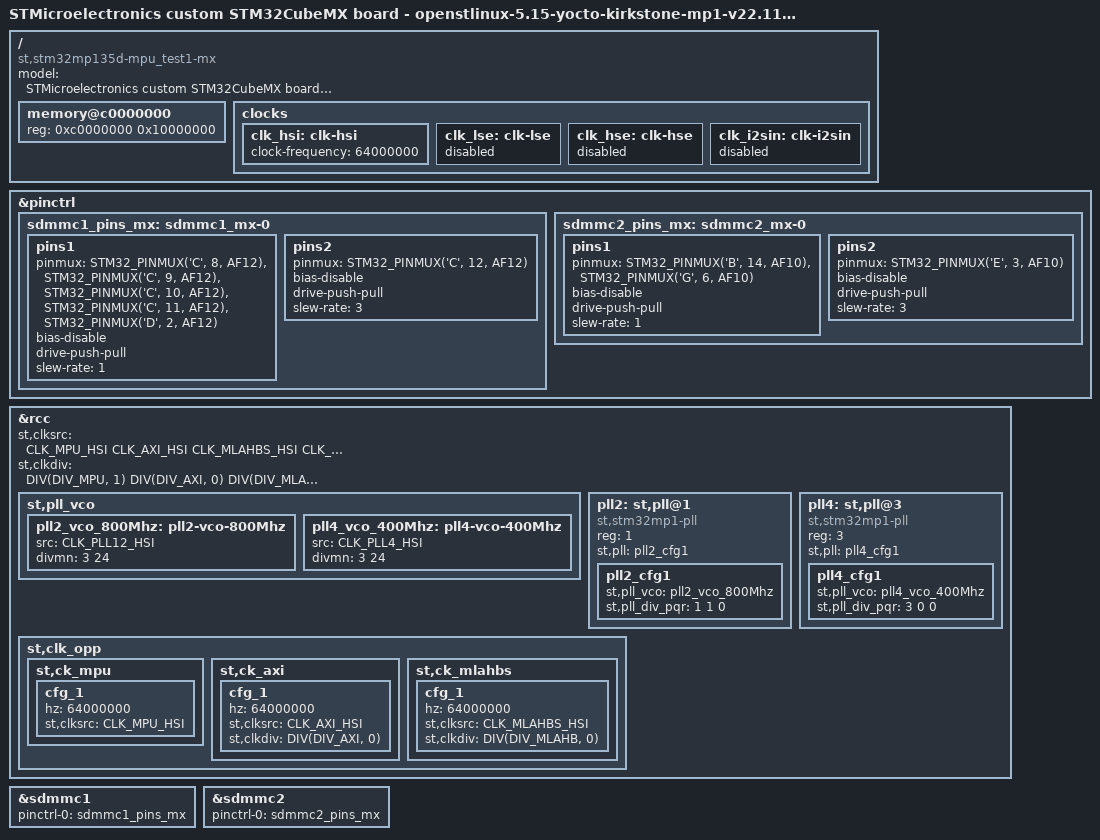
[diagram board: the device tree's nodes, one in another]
/* SPDX-License-Identifier: (GPL-2.0+ OR BSD-3-Clause) */
/*
 * Copyright (C) STMicroelectronics 2023 - All Rights Reserved
 * Author: STM32CubeMX code generation for STMicroelectronics.
 */

/* For more information on Device Tree configuration, please refer to
 * https://wiki.st.com/stm32mpu/wiki/Category:Device_tree_configuration
 */

/dts-v1/;
#include <dt-bindings/pinctrl/stm32-pinfunc.h>
#include <dt-bindings/clock/stm32mp13-clksrc.h>
#include "stm32mp13-mx.dtsi"

#include "stm32mp135.dtsi"
#include "stm32mp13xd.dtsi"
#include "stm32mp13-ddr.dtsi"

/* USER CODE BEGIN includes */
/* USER CODE END includes */

/ {
	model = "STMicroelectronics custom STM32CubeMX board - openstlinux-5.15-yocto-kirkstone-mp1-v22.11.23";
	compatible = "st,stm32mp135d-mpu_test1-mx", "st,stm32mp135";

	memory@c0000000 {
		device_type = "memory";
		reg = <0xc0000000 0x10000000>;

		/* USER CODE BEGIN memory */
		/* USER CODE END memory */
	};

	/* USER CODE BEGIN root */
	/* USER CODE END root */

	clocks {
		/* USER CODE BEGIN clocks */
		/* USER CODE END clocks */

		clk_hsi: clk-hsi {
			clock-frequency = <64000000>;

			/* USER CODE BEGIN clk_hsi */
			/* USER CODE END clk_hsi */
		};
		clk_lse: clk-lse {
			status = "disabled";

			/* USER CODE BEGIN clk_lse */
			/* USER CODE END clk_lse */
		};
		clk_hse: clk-hse {
			status = "disabled";

			/* USER CODE BEGIN clk_hse */
			/* USER CODE END clk_hse */
		};
		clk_i2sin: clk-i2sin {
			status = "disabled";

			/* USER CODE BEGIN clk_i2sin */
			/* USER CODE END clk_i2sin */
		};
	};

}; /*root*/

&pinctrl {
	sdmmc1_pins_mx: sdmmc1_mx-0 {
		pins1 {
			pinmux = <STM32_PINMUX('C', 8, AF12)>, /* SDMMC1_D0 */
					 <STM32_PINMUX('C', 9, AF12)>, /* SDMMC1_D1 */
					 <STM32_PINMUX('C', 10, AF12)>, /* SDMMC1_D2 */
					 <STM32_PINMUX('C', 11, AF12)>, /* SDMMC1_D3 */
					 <STM32_PINMUX('D', 2, AF12)>; /* SDMMC1_CMD */
			bias-disable;
			drive-push-pull;
			slew-rate = <1>;
		};
		pins2 {
			pinmux = <STM32_PINMUX('C', 12, AF12)>; /* SDMMC1_CK */
			bias-disable;
			drive-push-pull;
			slew-rate = <3>;
		};
	};

	sdmmc2_pins_mx: sdmmc2_mx-0 {
		pins1 {
			pinmux = <STM32_PINMUX('B', 14, AF10)>, /* SDMMC2_D0 */
					 <STM32_PINMUX('G', 6, AF10)>; /* SDMMC2_CMD */
			bias-disable;
			drive-push-pull;
			slew-rate = <1>;
		};
		pins2 {
			pinmux = <STM32_PINMUX('E', 3, AF10)>; /* SDMMC2_CK */
			bias-disable;
			drive-push-pull;
			slew-rate = <3>;
		};
	};

	/* USER CODE BEGIN pinctrl */
	/* USER CODE END pinctrl */
};

&rcc{
	status = "okay";

	/* USER CODE BEGIN rcc */
	/* USER CODE END rcc */

	st,clksrc = <
		CLK_MPU_HSI
		CLK_AXI_HSI
		CLK_MLAHBS_HSI
		CLK_RTC_LSI
		CLK_MCO1_DISABLED
		CLK_MCO2_DISABLED
		CLK_CKPER_DISABLED
		CLK_ETH1_PLL4P
		CLK_SDMMC1_HCLK6
		CLK_SDMMC2_HCLK6
		CLK_STGEN_HSI
	>;
	st,clkdiv = <
		DIV(DIV_MPU, 1)
		DIV(DIV_AXI, 0)
		DIV(DIV_MLAHB, 0)
		DIV(DIV_APB1, 0)
		DIV(DIV_APB2, 0)
		DIV(DIV_APB3, 0)
		DIV(DIV_APB4, 0)
		DIV(DIV_APB5, 0)
		DIV(DIV_APB6, 0)
		DIV(DIV_RTC, 0)
		DIV(DIV_MCO1, 0)
		DIV(DIV_MCO2, 0)
	>;
	st,pll_vco {
		pll2_vco_800Mhz: pll2-vco-800Mhz {
			src = < CLK_PLL12_HSI >;
			divmn = < 3 24 >;
		};
		pll4_vco_400Mhz: pll4-vco-400Mhz {
			src = < CLK_PLL4_HSI >;
			divmn = < 3 24 >;
		};

		/* USER CODE BEGIN rcc_st-pll_vco */
		/* USER CODE END rcc_st-pll_vco */
	};

	pll2:st,pll@1 {
		compatible = "st,stm32mp1-pll";
		reg = <1>;

		st,pll = < &pll2_cfg1 >;

		pll2_cfg1: pll2_cfg1 {
			st,pll_vco = < &pll2_vco_800Mhz >;
			st,pll_div_pqr = < 1 1 0 >;
		};
		/* USER CODE BEGIN pll2 */
		/* USER CODE END pll2 */
	};

	pll4:st,pll@3 {
		compatible = "st,stm32mp1-pll";
		reg = <3>;

		st,pll = < &pll4_cfg1 >;

		pll4_cfg1: pll4_cfg1 {
			st,pll_vco = < &pll4_vco_400Mhz >;
			st,pll_div_pqr = < 3 0 0 >;
		};
		/* USER CODE BEGIN pll4 */
		/* USER CODE END pll4 */
	};

	st,clk_opp {
		/* CK_MPU clock config for MP13 */
		st,ck_mpu {

			cfg_1 {
				hz = < 64000000 >;
				st,clksrc = < CLK_MPU_HSI >;
			};
			/* USER CODE BEGIN rcc_st-ck_mpu */
			/* USER CODE END rcc_st-ck_mpu */
		};

		/* CK_AXI clock config for MP13 */
		st,ck_axi {

			cfg_1 {
				hz = < 64000000 >;
				st,clksrc = < CLK_AXI_HSI >;
				st,clkdiv = < DIV(DIV_AXI, 0) >;
			};
			/* USER CODE BEGIN rcc_st-ck_axi */
			/* USER CODE END rcc_st-ck_axi */
		};

		/* CK_MLAHBS clock config for MP13 */
		st,ck_mlahbs {

			cfg_1 {
				hz = < 64000000 >;
				st,clksrc = < CLK_MLAHBS_HSI >;
				st,clkdiv = < DIV(DIV_MLAHB, 0) >;
			};

			/* USER CODE BEGIN rcc_st-ck_mlahbs */
			/* USER CODE END rcc_st-ck_mlahbs */
		};
	};
};

&sdmmc1{
	pinctrl-names = "default";
	pinctrl-0 = <&sdmmc1_pins_mx>;
	status = "okay";

	/* USER CODE BEGIN sdmmc1 */
	/* USER CODE END sdmmc1 */
};

&sdmmc2{
	pinctrl-names = "default";
	pinctrl-0 = <&sdmmc2_pins_mx>;
	status = "okay";

	/* USER CODE BEGIN sdmmc2 */
	/* USER CODE END sdmmc2 */
};

/* USER CODE BEGIN addons */
/* USER CODE END addons */

